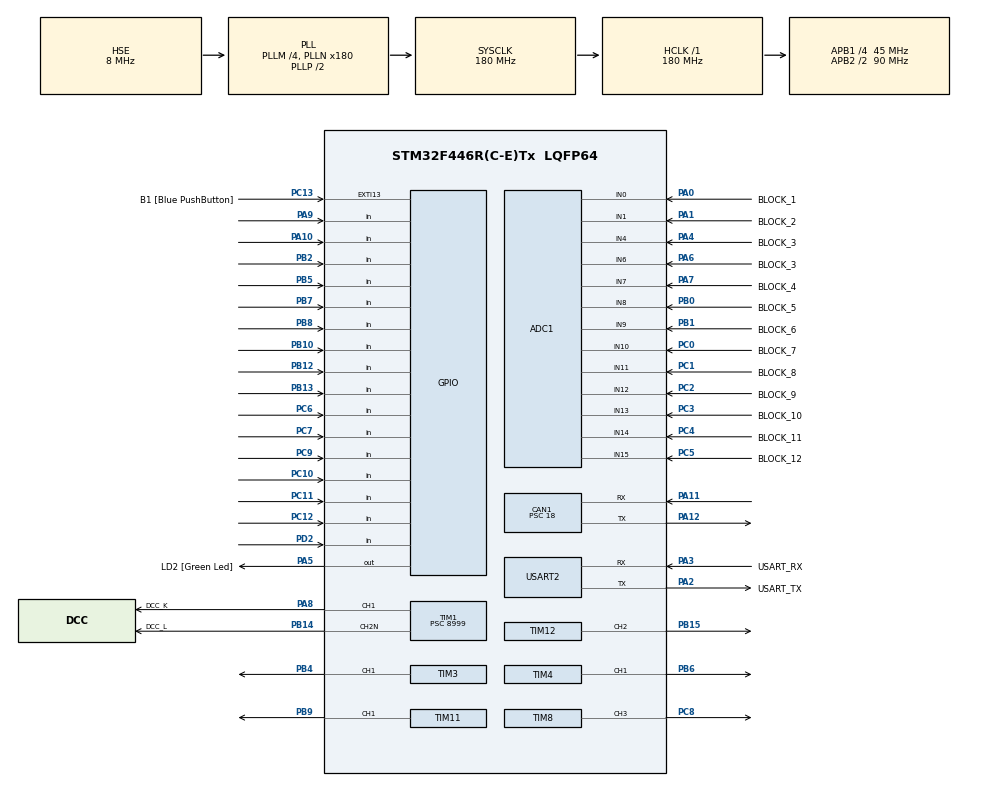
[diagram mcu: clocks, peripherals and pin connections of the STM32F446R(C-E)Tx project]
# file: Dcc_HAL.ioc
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ADC1.Channel-0\#ChannelRegularConversion=ADC_CHANNEL_0
ADC1.ClockPrescaler=ADC_CLOCK_SYNC_PCLK_DIV8
ADC1.DMAContinuousRequests=ENABLE
ADC1.InjNumberOfConversion=0
ADC1.NbrOfConversion=1
ADC1.NbrOfConversionFlag=1
ADC1.Rank-0\#ChannelRegularConversion=1
ADC1.SamplingTime-0\#ChannelRegularConversion=ADC_SAMPLETIME_3CYCLES
ADC1.master=1
CAN1.ABOM=DISABLE
CAN1.AWUM=DISABLE
CAN1.BS1=CAN_BS1_14TQ
CAN1.BS2=CAN_BS2_5TQ
CAN1.CalculateTimeBit=8000
CAN1.CalculateTimeQuantum=400.0
CAN1.Mode=CAN_MODE_SILENT_LOOPBACK
CAN1.Prescaler=18
CAN1.SJW=CAN_SJW_1TQ
Dma.ADC1.0.Direction=DMA_PERIPH_TO_MEMORY
Dma.ADC1.0.FIFOMode=DMA_FIFOMODE_DISABLE
Dma.ADC1.0.Instance=DMA2_Stream0
Dma.ADC1.0.MemDataAlignment=DMA_MDATAALIGN_HALFWORD
Dma.ADC1.0.MemInc=DMA_MINC_ENABLE
Dma.ADC1.0.Mode=DMA_NORMAL
Dma.ADC1.0.PeriphDataAlignment=DMA_PDATAALIGN_HALFWORD
Dma.ADC1.0.PeriphInc=DMA_PINC_DISABLE
Dma.ADC1.0.Priority=DMA_PRIORITY_LOW
Dma.Request0=ADC1
Mcu.Family=STM32F4
Mcu.Name=STM32F446R(C-E)Tx
Mcu.Package=LQFP64
Mcu.UserConstants=DCC_ZERO_BIT_TIME_MS,100;DCC_ONE_BIT_TIME_MS,58
NVIC.DMA2_Stream0_IRQn=true\:7\:0\:true\:false\:true
NVIC.EXTI15_10_IRQn=true\:7\:1\:true\:false\:true
NVIC.PriorityGroup=NVIC_PRIORITYGROUP_3
NVIC.TIM1_CC_IRQn=true\:6\:0\:true\:false\:true
PA0-WKUP.GPIO_Label=BLOCK_1
PA0-WKUP.Signal=ADCx_IN0
PA1.GPIO_Label=BLOCK_2
PA1.Signal=ADCx_IN1
PA10.Signal=GPIO_Input
PA11.Mode=Master
PA11.Signal=CAN1_RX
PA12.Mode=Master
PA12.Signal=CAN1_TX
PA13.GPIO_Label=TMS
PA13.Signal=SYS_JTMS-SWDIO
PA14.GPIO_Label=TCK
PA14.Signal=SYS_JTCK-SWCLK
PA15.Signal=S_TIM2_CH1_ETR
PA2.GPIO_Label=USART_TX
PA2.Mode=Asynchronous
PA2.Signal=USART2_TX
PA3.GPIO_Label=USART_RX
PA3.Mode=Asynchronous
PA3.Signal=USART2_RX
PA4.GPIO_Label=BLOCK_3
PA4.Signal=ADCx_IN4
PA5.GPIO_Label=LD2 [Green Led]
PA5.Signal=GPIO_Output
PA6.GPIO_Label=BLOCK_3
PA6.Signal=ADCx_IN6
PA7.GPIO_Label=BLOCK_4
PA7.Signal=ADCx_IN7
PA8.GPIO_Label=DCC_K
PA8.Signal=S_TIM1_CH1
PA9.Signal=GPIO_Input
PB0.GPIO_Label=BLOCK_5
PB0.Signal=ADCx_IN8
PB1.GPIO_Label=BLOCK_6
PB1.Signal=ADCx_IN9
PB10.Signal=GPIO_Input
PB12.Signal=GPIO_Input
PB13.Signal=GPIO_Input
PB14.GPIO_Label=DCC_L
PB14.Mode=PWM Generation2 CH2N
PB14.Signal=TIM1_CH2N
PB15.Signal=S_TIM12_CH2
PB2.Signal=GPIO_Input
PB3.GPIO_Label=SWO
PB3.Signal=SYS_JTDO-SWO
PB4.Signal=S_TIM3_CH1
PB5.Signal=GPIO_Input
PB6.Signal=S_TIM4_CH1
PB7.Signal=GPIO_Input
PB8.Signal=GPIO_Input
PB9.Signal=S_TIM11_CH1
PC0.GPIO_Label=BLOCK_7
PC0.Signal=ADCx_IN10
PC1.GPIO_Label=BLOCK_8
PC1.Signal=ADCx_IN11
PC10.Signal=GPIO_Input
PC11.Signal=GPIO_Input
PC12.Signal=GPIO_Input
PC13.GPIO_Label=B1 [Blue PushButton]
PC13.GPIO_ModeDefaultEXTI=GPIO_MODE_IT_RISING
PC13.Signal=GPXTI13
PC14-OSC32_IN.Mode=LSE-External-Oscillator
PC14-OSC32_IN.Signal=RCC_OSC32_IN
PC15-OSC32_OUT.Mode=LSE-External-Oscillator
PC15-OSC32_OUT.Signal=RCC_OSC32_OUT
PC2.GPIO_Label=BLOCK_9
PC2.Signal=ADCx_IN12
PC3.GPIO_Label=BLOCK_10
PC3.Signal=ADCx_IN13
PC4.GPIO_Label=BLOCK_11
PC4.Signal=ADCx_IN14
PC5.GPIO_Label=BLOCK_12
PC5.Signal=ADCx_IN15
PC6.Signal=GPIO_Input
PC7.Signal=GPIO_Input
PC8.Signal=S_TIM8_CH3
PC9.Signal=GPIO_Input
PD2.Signal=GPIO_Input
PH0-OSC_IN.Mode=HSE-External-Oscillator
PH0-OSC_IN.Signal=RCC_OSC_IN
PH1-OSC_OUT.Mode=HSE-External-Oscillator
PH1-OSC_OUT.Signal=RCC_OSC_OUT
ProjectManager.HeapSize=0x200
ProjectManager.StackSize=0x400
ProjectManager.TargetToolchain=SW4STM32
RCC.AHBFreq_Value=180000000
RCC.APB1CLKDivider=RCC_HCLK_DIV4
RCC.APB1Freq_Value=45000000
RCC.APB1TimFreq_Value=90000000
RCC.APB2CLKDivider=RCC_HCLK_DIV2
RCC.APB2Freq_Value=90000000
RCC.APB2TimFreq_Value=180000000
RCC.CortexFreq_Value=180000000
RCC.FLatency-AdvancedSettings=FLASH_LATENCY_5
RCC.HCLKFreq_Value=180000000
RCC.HSE_VALUE=8000000
RCC.HSI_VALUE=16000000
RCC.PLLM=4
RCC.PLLN=180
RCC.PLLSourceVirtual=RCC_PLLSOURCE_HSE
RCC.RCC_RTC_Clock_SourceVirtual=RCC_RTCCLKSOURCE_LSE
RCC.SYSCLKFreq_VALUE=180000000
RCC.SYSCLKSource=RCC_SYSCLKSOURCE_PLLCLK
RCC.USBFreq_Value=180000000
RCC.VCOOutputFreq_Value=360000000
RTC.Date=1
RTC.Month=RTC_MONTH_SEPTEMBER
RTC.WeekDay=RTC_WEEKDAY_THURSDAY
RTC.Year=16
SH.ADCx_IN0.0=ADC1_IN0,IN0
SH.ADCx_IN1.0=ADC1_IN1,IN1
SH.ADCx_IN10.0=ADC1_IN10,IN10
SH.ADCx_IN11.0=ADC1_IN11,IN11
SH.ADCx_IN12.0=ADC1_IN12,IN12
SH.ADCx_IN13.0=ADC1_IN13,IN13
SH.ADCx_IN14.0=ADC1_IN14,IN14
SH.ADCx_IN15.0=ADC1_IN15,IN15
SH.ADCx_IN4.0=ADC1_IN4,IN4
SH.ADCx_IN6.0=ADC1_IN6,IN6
SH.ADCx_IN7.0=ADC1_IN7,IN7
SH.ADCx_IN8.0=ADC1_IN8,IN8
SH.ADCx_IN9.0=ADC1_IN9,IN9
SH.S_TIM11_CH1.0=TIM11_CH1,PWM Generation1 CH1
SH.S_TIM12_CH2.0=TIM12_CH2,PWM Generation2 CH2
SH.S_TIM1_CH1.0=TIM1_CH1,PWM Generation1 CH1
SH.S_TIM2_CH1_ETR.0=TIM2_CH1
SH.S_TIM3_CH1.0=TIM3_CH1,PWM Generation1 CH1
SH.S_TIM4_CH1.0=TIM4_CH1,PWM Generation1 CH1
SH.S_TIM8_CH3.0=TIM8_CH3,PWM Generation3 CH3
TIM1.Channel-PWM\ Generation2\ CH2N=TIM_CHANNEL_2
TIM1.CounterMode=TIM_COUNTERMODE_CENTERALIGNED3
TIM1.Period=8999
TIM1.Prescaler=8999
TIM1.Pulse-PWM\ Generation1\ CH1=4499
TIM1.Pulse-PWM\ Generation2\ CH2N=4499
TIM12.Channel-PWM\ Generation2\ CH2=TIM_CHANNEL_2
TIM8.Channel-PWM\ Generation3\ CH3=TIM_CHANNEL_3
VP_ADC1_TempSens_Input.Mode=IN-TempSens
VP_RTC_VS_RTC_Alarm_A_Intern.Mode=Alarm A
VP_RTC_VS_RTC_Alarm_B_Intern.Mode=Alarm B
VP_RTC_VS_RTC_WakeUp_intern.Mode=WakeUp
VP_TIM11_VS_ClockSourceINT.Mode=Enable_Timer
VP_TIM1_VS_ClockSourceINT.Mode=Internal
VP_TIM3_VS_ClockSourceINT.Mode=Internal
VP_TIM8_VS_ClockSourceINT.Mode=Internal
board=NUCLEO-F446RE

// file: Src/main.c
/**
  ******************************************************************************
  * File Name          : main.c
  * Description        : Main program body
  ******************************************************************************
  *
  * COPYRIGHT(c) 2016 STMicroelectronics
  *
  * Redistribution and use in source and binary forms, with or without modification,
  * are permitted provided that the following conditions are met:
  *   1. Redistributions of source code must retain the above copyright notice,
  *      this list of conditions and the following disclaimer.
  *   2. Redistributions in binary form must reproduce the above copyright notice,
  *      this list of conditions and the following disclaimer in the documentation
  *      and/or other materials provided with the distribution.
  *   3. Neither the name of STMicroelectronics nor the names of its contributors
  *      may be used to endorse or promote products derived from this software
  *      without specific prior written permission.
  *
  * THIS SOFTWARE IS PROVIDED BY THE COPYRIGHT HOLDERS AND CONTRIBUTORS "AS IS"
  * AND ANY EXPRESS OR IMPLIED WARRANTIES, INCLUDING, BUT NOT LIMITED TO, THE
  * IMPLIED WARRANTIES OF MERCHANTABILITY AND FITNESS FOR A PARTICULAR PURPOSE ARE
  * DISCLAIMED. IN NO EVENT SHALL THE COPYRIGHT HOLDER OR CONTRIBUTORS BE LIABLE
  * FOR ANY DIRECT, INDIRECT, INCIDENTAL, SPECIAL, EXEMPLARY, OR CONSEQUENTIAL
  * DAMAGES (INCLUDING, BUT NOT LIMITED TO, PROCUREMENT OF SUBSTITUTE GOODS OR
  * SERVICES; LOSS OF USE, DATA, OR PROFITS; OR BUSINESS INTERRUPTION) HOWEVER
  * CAUSED AND ON ANY THEORY OF LIABILITY, WHETHER IN CONTRACT, STRICT LIABILITY,
  * OR TORT (INCLUDING NEGLIGENCE OR OTHERWISE) ARISING IN ANY WAY OUT OF THE USE
  * OF THIS SOFTWARE, EVEN IF ADVISED OF THE POSSIBILITY OF SUCH DAMAGE.
  *
  ******************************************************************************
  */
#include "stm32f4xx_hal.h"
#include "adc.h"
#include "can.h"
#include "dma.h"
#include "rtc.h"
#include "tim.h"
#include "usart.h"
#include "gpio.h"

/* USER CODE BEGIN Includes */
#include "dcc_hal.h"
/* USER CODE END Includes */

/* USER CODE BEGIN PV */
/* Private variables ---------------------------------------------------------*/

/* USER CODE END PV */

void SystemClock_Config(void);
void Error_Handler(void);

/* USER CODE BEGIN PFP */
/* Private function prototypes -----------------------------------------------*/

/* USER CODE END PFP */

int main(void)
{

  /* MCU Configuration----------------------------------------------------------*/

  /* Reset of all peripherals, Initializes the Flash interface and the Systick. */
  HAL_Init();

  /* Configure the system clock */
  SystemClock_Config();

  /* Initialize all configured peripherals */
  MX_GPIO_Init();
  MX_DMA_Init();
  MX_USART2_UART_Init();
  MX_CAN1_Init();
  MX_ADC1_Init();
  MX_RTC_Init();
  MX_TIM1_Init();
  MX_TIM4_Init();
  MX_TIM8_Init();
  MX_TIM11_Init();
  MX_TIM12_Init();
  MX_TIM3_Init();

  /* USER CODE BEGIN 2 */
  serial_print("Starting application\n");
  HAL_CAN_StateTypeDef can_status;
  can_status = HAL_CAN_GetState(&hcan1);
  serial_print("CAN Status: %d\n", can_status);
  /* USER CODE END 2 */

  /* Infinite loop */
  while (1)
  {

  }

}

/** System Clock Configuration
*/
void SystemClock_Config(void)
{

  RCC_OscInitTypeDef RCC_OscInitStruct;
  RCC_ClkInitTypeDef RCC_ClkInitStruct;
  RCC_PeriphCLKInitTypeDef PeriphClkInitStruct;

  __HAL_RCC_PWR_CLK_ENABLE();

  __HAL_PWR_VOLTAGESCALING_CONFIG(PWR_REGULATOR_VOLTAGE_SCALE1);

  RCC_OscInitStruct.OscillatorType = RCC_OSCILLATORTYPE_HSE|RCC_OSCILLATORTYPE_LSE;
  RCC_OscInitStruct.HSEState = RCC_HSE_ON;
  RCC_OscInitStruct.LSEState = RCC_LSE_ON;
  RCC_OscInitStruct.PLL.PLLState = RCC_PLL_ON;
  RCC_OscInitStruct.PLL.PLLSource = RCC_PLLSOURCE_HSE;
  RCC_OscInitStruct.PLL.PLLM = 4;
  RCC_OscInitStruct.PLL.PLLN = 180;
  RCC_OscInitStruct.PLL.PLLP = RCC_PLLP_DIV2;
  RCC_OscInitStruct.PLL.PLLQ = 2;
  RCC_OscInitStruct.PLL.PLLR = 2;
  if (HAL_RCC_OscConfig(&RCC_OscInitStruct) != HAL_OK)
  {
    Error_Handler();
  }

  if (HAL_PWREx_EnableOverDrive() != HAL_OK)
  {
    Error_Handler();
  }

  RCC_ClkInitStruct.ClockType = RCC_CLOCKTYPE_HCLK|RCC_CLOCKTYPE_SYSCLK
                              |RCC_CLOCKTYPE_PCLK1|RCC_CLOCKTYPE_PCLK2;
  RCC_ClkInitStruct.SYSCLKSource = RCC_SYSCLKSOURCE_PLLCLK;
  RCC_ClkInitStruct.AHBCLKDivider = RCC_SYSCLK_DIV1;
  RCC_ClkInitStruct.APB1CLKDivider = RCC_HCLK_DIV4;
  RCC_ClkInitStruct.APB2CLKDivider = RCC_HCLK_DIV2;
  if (HAL_RCC_ClockConfig(&RCC_ClkInitStruct, FLASH_LATENCY_5) != HAL_OK)
  {
    Error_Handler();
  }

  PeriphClkInitStruct.PeriphClockSelection = RCC_PERIPHCLK_RTC;
  PeriphClkInitStruct.RTCClockSelection = RCC_RTCCLKSOURCE_LSE;
  if (HAL_RCCEx_PeriphCLKConfig(&PeriphClkInitStruct) != HAL_OK)
  {
    Error_Handler();
  }

  HAL_SYSTICK_Config(HAL_RCC_GetHCLKFreq()/1000);

  HAL_SYSTICK_CLKSourceConfig(SYSTICK_CLKSOURCE_HCLK);

  /* SysTick_IRQn interrupt configuration */
  HAL_NVIC_SetPriority(SysTick_IRQn, 0, 0);
}

void Error_Handler(void)
{
  /* USER CODE BEGIN Error_Handler */
  /* User can add his own implementation to report the HAL error return state */
//  while(1)
//  {
//  }
  static int i = 0;
  i++;
  serial_print("Error in Init: %d\n", i);
  /* USER CODE END Error_Handler */
}

/************************ (C) COPYRIGHT STMicroelectronics *****END OF FILE****/
